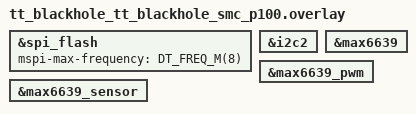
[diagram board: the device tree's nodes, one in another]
/*
 * Copyright (c) 2025 Tenstorrent AI ULC
 * SPDX-License-Identifier: Apache-2.0
 */
#include <freq.h>

/* P100A has octal flash, so use a slower frequency for flash access */
/* Up to 10MHz has passed experimentally, use 8 to be safe */
&spi_flash {
	mspi-max-frequency = <DT_FREQ_M(8)>;
};

&i2c2 {
	status = "okay";
};

&max6639 {
	status = "okay";
};

&max6639_pwm {
	status = "okay";
};

&max6639_sensor {
	status = "okay";
};
